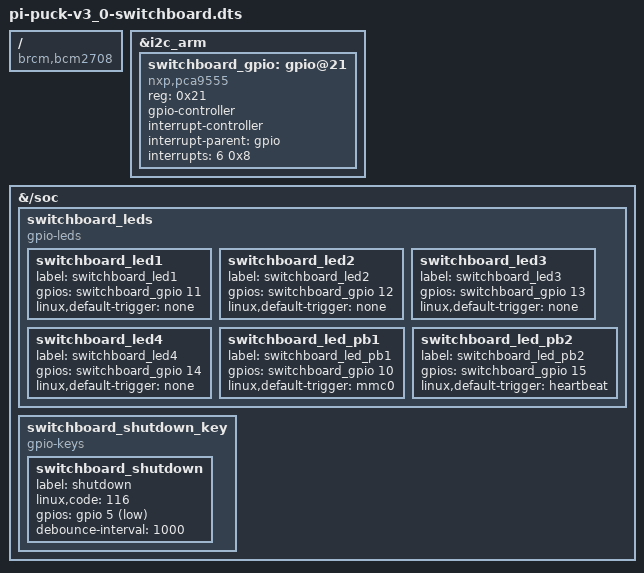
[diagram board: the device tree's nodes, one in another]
/dts-v1/;
/plugin/;

/ {
	compatible = "brcm,bcm2708";

	/* I2C devices */
	fragment@0 {
		target = <&i2c_arm>;
		__overlay__ {
			#address-cells = <1>;
			#size-cells = <0>;
			status = "okay";
			switchboard_gpio: gpio@21 {
				compatible = "nxp,pca9555";
				reg = <0x21>;
				gpio-controller;
				#gpio-cells = <2>;
				interrupt-controller;
				#interrupt-cells = <2>;
				interrupt-parent = <&gpio>;
				interrupts = <6 0x8>;
			};
		};
	};

	/* LEDs */
	fragment@1 {
		target-path = "/soc";
		__overlay__ {
			switchboard_leds {
				compatible = "gpio-leds";
				switchboard_led1 {
					label = "switchboard_led1";
					gpios = <&switchboard_gpio 11 0>;
					linux,default-trigger = "none";
				};
				switchboard_led2 {
					label = "switchboard_led2";
					gpios = <&switchboard_gpio 12 0>;
					linux,default-trigger = "none";
				};
				switchboard_led3 {
					label = "switchboard_led3";
					gpios = <&switchboard_gpio 13 0>;
					linux,default-trigger = "none";
				};
				switchboard_led4 {
					label = "switchboard_led4";
					gpios = <&switchboard_gpio 14 0>;
					linux,default-trigger = "none";
				};
				switchboard_led_pb1 {
					label = "switchboard_led_pb1";
					gpios = <&switchboard_gpio 10 0>;
					linux,default-trigger = "mmc0";
				};
				switchboard_led_pb2 {
					label = "switchboard_led_pb2";
					gpios = <&switchboard_gpio 15 0>;
					linux,default-trigger = "heartbeat";
				};
			};
		};
	};

	/* DIP switch keys */
	fragment@2 {
		target-path = "/soc";
		__dormant__ {
			switchboard_dip_switch_keys {
				compatible = "gpio-keys";
				switchboard_sw1 {
					label = "switchboard_sw1";
					gpios = <&switchboard_gpio 0 1>; // SW1
					linux,code = <256>;
				};
				switchboard_sw2 {
					label = "switchboard_sw2";
					gpios = <&switchboard_gpio 1 1>; // SW2
					linux,code = <257>;
				};
				switchboard_sw3 {
					label = "switchboard_sw3";
					gpios = <&switchboard_gpio 2 1>; // SW3
					linux,code = <258>;
				};
				switchboard_sw4 {
					label = "switchboard_sw4";
					gpios = <&switchboard_gpio 3 1>; // SW4
					linux,code = <259>;
				};
			};
		};
	};

	/* Navigation switch keys */
	fragment@3 {
		target-path = "/soc";
		__dormant__ {
			switchboard_nav_switch_keys {
				compatible = "gpio-keys";
				switchboard_up {
					label = "switchboard_up";
					gpios = <&switchboard_gpio 4 1>; // UP
					linux,code = <103>; // KEY_UP
				};
				switchboard_down {
					label = "switchboard_down";
					gpios = <&switchboard_gpio 5 1>; // DOWN
					linux,code = <108>; // KEY_DOWN
				};
				switchboard_left {
					label = "switchboard_left";
					gpios = <&switchboard_gpio 6 1>; // LEFT
					linux,code = <105>; // KEY_LEFT
				};
				switchboard_right {
					label = "switchboard_right";
					gpios = <&switchboard_gpio 7 1>; // RIGHT
					linux,code = <106>; // KEY_RIGHT
				};
				switchboard_centre {
					label = "switchboard_centre";
					gpios = <&switchboard_gpio 8 1>; // CENTRE
					linux,code = <28>; // KEY_ENTER
				};
				switchboard_pb1 {
					label = "switchboard_pb1";
					gpios = <&switchboard_gpio 9 1>; // SW1
					linux,code = <30>; // KEY_A
				};
			};
		};
	};

	/* Shutdown button key */
	fragment@4 {
		target-path = "/soc";
		__overlay__ {
			switchboard_shutdown_key {
				compatible = "gpio-keys";
				switchboard_shutdown: switchboard_shutdown {
					label = "shutdown";
					linux,code = <116>; // KEY_POWER
					gpios = <&gpio 5 1>;
					debounce-interval = <1000>;
				};
			};
		};
	};

	__overrides__ {
		dip_keys = <0>,"+2";
		nav_keys = <0>,"+3";
		shutdown_key_disable = <0>,"-4";
		shutdown_key_debounce = <&switchboard_shutdown>,"debounce-interval:0";
	};
};
